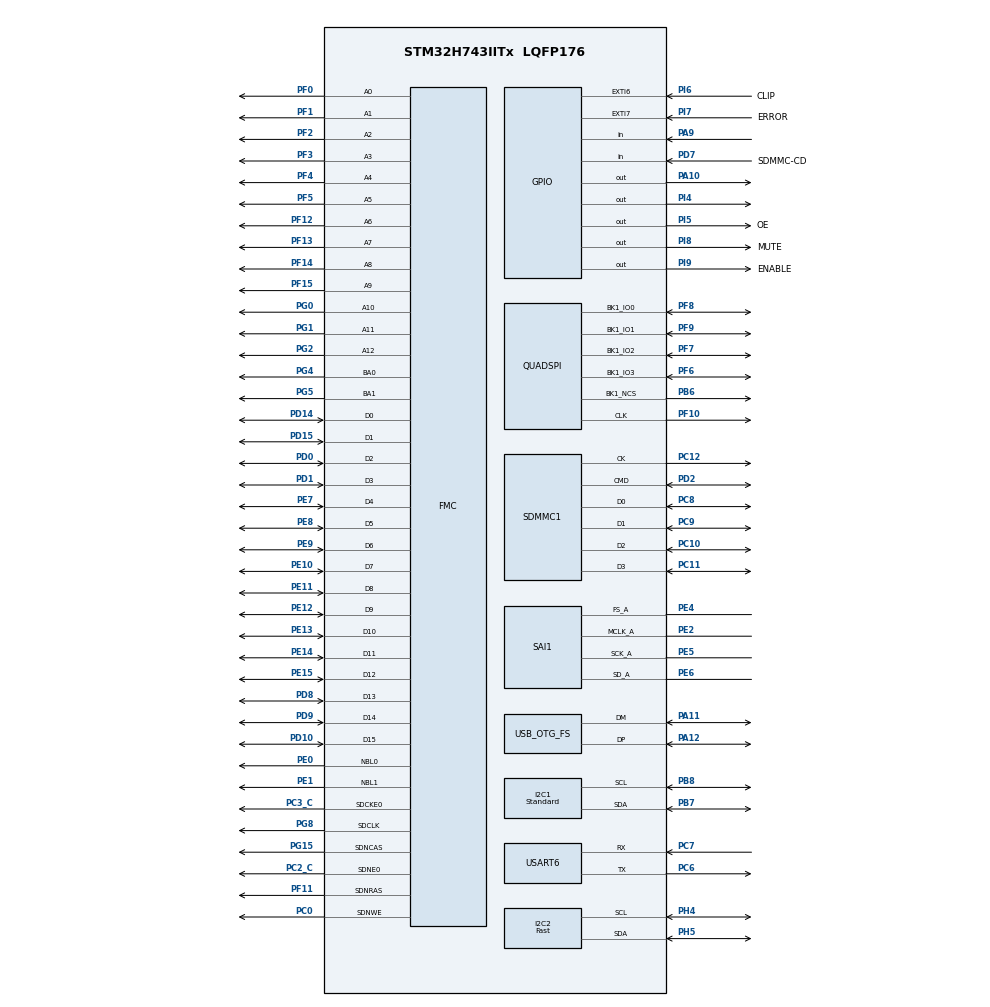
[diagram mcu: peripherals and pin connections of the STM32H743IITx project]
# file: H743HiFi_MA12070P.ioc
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CORTEX_M7.CPU_DCache=Disabled
CORTEX_M7.CPU_ICache=Disabled
CORTEX_M7.Enable_S-Cortex_Memory_Protection_Unit_Region1_Settings_S=MPU_REGION_ENABLE
CORTEX_M7.Size_Spec=MPU_REGION_SIZE_32B
CORTEX_M7.default_mode_Activation=0
Dma.I2C2_RX.0.Direction=DMA_PERIPH_TO_MEMORY
Dma.I2C2_RX.0.EventEnable=DISABLE
Dma.I2C2_RX.0.FIFOMode=DMA_FIFOMODE_DISABLE
Dma.I2C2_RX.0.Instance=DMA1_Stream0
Dma.I2C2_RX.0.MemDataAlignment=DMA_MDATAALIGN_BYTE
Dma.I2C2_RX.0.MemInc=DMA_MINC_ENABLE
Dma.I2C2_RX.0.Mode=DMA_CIRCULAR
Dma.I2C2_RX.0.PeriphDataAlignment=DMA_PDATAALIGN_BYTE
Dma.I2C2_RX.0.PeriphInc=DMA_PINC_DISABLE
Dma.I2C2_RX.0.Polarity=HAL_DMAMUX_REQ_GEN_RISING
Dma.I2C2_RX.0.Priority=DMA_PRIORITY_HIGH
Dma.I2C2_RX.0.RequestNumber=1
Dma.I2C2_RX.0.SignalID=NONE
Dma.I2C2_RX.0.SyncEnable=DISABLE
Dma.I2C2_RX.0.SyncPolarity=HAL_DMAMUX_SYNC_NO_EVENT
Dma.I2C2_RX.0.SyncRequestNumber=1
Dma.I2C2_RX.0.SyncSignalID=NONE
Dma.I2C2_TX.1.Direction=DMA_MEMORY_TO_PERIPH
Dma.I2C2_TX.1.EventEnable=DISABLE
Dma.I2C2_TX.1.FIFOMode=DMA_FIFOMODE_DISABLE
Dma.I2C2_TX.1.Instance=DMA1_Stream1
Dma.I2C2_TX.1.MemDataAlignment=DMA_MDATAALIGN_BYTE
Dma.I2C2_TX.1.MemInc=DMA_MINC_ENABLE
Dma.I2C2_TX.1.Mode=DMA_NORMAL
Dma.I2C2_TX.1.PeriphDataAlignment=DMA_PDATAALIGN_BYTE
Dma.I2C2_TX.1.PeriphInc=DMA_PINC_DISABLE
Dma.I2C2_TX.1.Polarity=HAL_DMAMUX_REQ_GEN_RISING
Dma.I2C2_TX.1.Priority=DMA_PRIORITY_HIGH
Dma.I2C2_TX.1.RequestNumber=1
Dma.I2C2_TX.1.SignalID=NONE
Dma.I2C2_TX.1.SyncEnable=DISABLE
Dma.I2C2_TX.1.SyncPolarity=HAL_DMAMUX_SYNC_NO_EVENT
Dma.I2C2_TX.1.SyncRequestNumber=1
Dma.I2C2_TX.1.SyncSignalID=NONE
Dma.Request0=I2C2_RX
Dma.Request1=I2C2_TX
Dma.Request2=SAI1_A
Dma.SAI1_A.2.Direction=DMA_MEMORY_TO_PERIPH
Dma.SAI1_A.2.EventEnable=DISABLE
Dma.SAI1_A.2.FIFOMode=DMA_FIFOMODE_ENABLE
Dma.SAI1_A.2.FIFOThreshold=DMA_FIFO_THRESHOLD_FULL
Dma.SAI1_A.2.Instance=DMA1_Stream2
Dma.SAI1_A.2.MemBurst=DMA_MBURST_SINGLE
Dma.SAI1_A.2.MemDataAlignment=DMA_MDATAALIGN_WORD
Dma.SAI1_A.2.MemInc=DMA_MINC_ENABLE
Dma.SAI1_A.2.Mode=DMA_CIRCULAR
Dma.SAI1_A.2.PeriphBurst=DMA_PBURST_SINGLE
Dma.SAI1_A.2.PeriphDataAlignment=DMA_PDATAALIGN_WORD
Dma.SAI1_A.2.PeriphInc=DMA_PINC_DISABLE
Dma.SAI1_A.2.Polarity=HAL_DMAMUX_REQ_GEN_RISING
Dma.SAI1_A.2.Priority=DMA_PRIORITY_HIGH
Dma.SAI1_A.2.RequestNumber=1
Dma.SAI1_A.2.SignalID=NONE
Dma.SAI1_A.2.SyncEnable=DISABLE
Dma.SAI1_A.2.SyncPolarity=HAL_DMAMUX_SYNC_NO_EVENT
Dma.SAI1_A.2.SyncRequestNumber=1
Dma.SAI1_A.2.SyncSignalID=NONE
FATFS.BSP.number=1
FATFS._CODE_PAGE=936
FATFS._FS_EXFAT=1
FATFS._FS_RPATH=2
FATFS._FS_TINY=0
FATFS._LFN_UNICODE=0
FATFS._MAX_SS=512
FATFS._STRF_ENCODE=0
FATFS._USE_EXPAND=1
FATFS._USE_FIND=1
FATFS._USE_FORWARD=1
FATFS._USE_LABEL=1
FATFS._USE_LFN=3
FATFS0.BSP.STBoard=false
FATFS0.BSP.api=Unknown
FATFS0.BSP.instance=PD7
FATFS0.BSP.ip=GPIO
FATFS0.BSP.mode=Input
FATFS0.BSP.name=Detect_SDIO
FATFS0.BSP.solution=PD7
FMC.BankMapConfig=FMC_SWAPBMAP_DISABLE
FMC.CASLatency1=FMC_SDRAM_CAS_LATENCY_3
FMC.ExitSelfRefreshDelay1=7
FMC.LoadToActiveDelay1=2
FMC.RCDDelay1=2
FMC.RPDelay1=2
FMC.RPDelay2=2
FMC.ReadBurst1=FMC_SDRAM_RBURST_ENABLE
FMC.ReadBurst2=FMC_SDRAM_RBURST_ENABLE
FMC.ReadPipeDelay1=FMC_SDRAM_RPIPE_DELAY_2
FMC.RowCycleDelay1=7
FMC.RowCycleDelay2=7
FMC.SDClockPeriod1=FMC_SDRAM_CLOCK_PERIOD_2
FMC.SelfRefreshTime1=4
FMC.WriteRecoveryTime1=3
FREERTOS.Tasks01=defaultTask,24,1024,StartDefaultTask,Default,NULL,Dynamic,NULL,NULL;pcm_data,8,16384,pcm_data_task,Default,NULL,Dynamic,NULL,NULL;iic_check,8,128,iic_check_task,Default,NULL,Dynamic,NULL,NULL
FREERTOS.configCHECK_FOR_STACK_OVERFLOW=1
FREERTOS.configENABLE_FPU=1
FREERTOS.configTOTAL_HEAP_SIZE=300000
FREERTOS.configUSE_NEWLIB_REENTRANT=1
I2C1.CustomTiming=Enabled
I2C1.I2C_Speed_Mode=I2C_Standard
I2C1.Speed=50
I2C1.Timing=0x00201A3B
I2C2.AddressingMode=I2C_ADDRESSINGMODE_10BIT
I2C2.DualAddressMode=I2C_DUALADDRESS_DISABLE
I2C2.GeneralCallMode=I2C_GENERALCALL_DISABLE
I2C2.I2C_Speed_Mode=I2C_Fast
I2C2.OwnAddress=0xa0
I2C2.Timing=0x00000001
Mcu.Family=STM32H7
Mcu.Name=STM32H743IITx
Mcu.Package=LQFP176
Mdma.MDMA_Channel0.QUADSPI_FIFO_TH.0.BlockCount=0
Mdma.MDMA_Channel0.QUADSPI_FIFO_TH.0.BlockDataLength=0
Mdma.MDMA_Channel0.QUADSPI_FIFO_TH.0.BufferTransferLength=1
Mdma.MDMA_Channel0.QUADSPI_FIFO_TH.0.CircularMode=MDMA_LINEAR_LIST
Mdma.MDMA_Channel0.QUADSPI_FIFO_TH.0.DataAlignment=MDMA_DATAALIGN_PACKENABLE
Mdma.MDMA_Channel0.QUADSPI_FIFO_TH.0.DestBlockAddressOffset=0
Mdma.MDMA_Channel0.QUADSPI_FIFO_TH.0.DestBurst=MDMA_DEST_BURST_SINGLE
Mdma.MDMA_Channel0.QUADSPI_FIFO_TH.0.DestDataSize=MDMA_DEST_DATASIZE_BYTE
Mdma.MDMA_Channel0.QUADSPI_FIFO_TH.0.DestinationInc=MDMA_DEST_INC_BYTE
Mdma.MDMA_Channel0.QUADSPI_FIFO_TH.0.DstAddress=0
Mdma.MDMA_Channel0.QUADSPI_FIFO_TH.0.Endianness=MDMA_LITTLE_ENDIANNESS_PRESERVE
Mdma.MDMA_Channel0.QUADSPI_FIFO_TH.0.Instance=MDMA_Channel0
Mdma.MDMA_Channel0.QUADSPI_FIFO_TH.0.MaskAddress=0
Mdma.MDMA_Channel0.QUADSPI_FIFO_TH.0.MaskData=0
Mdma.MDMA_Channel0.QUADSPI_FIFO_TH.0.Priority=MDMA_PRIORITY_LOW
Mdma.MDMA_Channel0.QUADSPI_FIFO_TH.0.Rank=First
Mdma.MDMA_Channel0.QUADSPI_FIFO_TH.0.SourceBlockAddressOffset=0
Mdma.MDMA_Channel0.QUADSPI_FIFO_TH.0.SourceBurst=MDMA_SOURCE_BURST_SINGLE
Mdma.MDMA_Channel0.QUADSPI_FIFO_TH.0.SourceDataSize=MDMA_SRC_DATASIZE_BYTE
Mdma.MDMA_Channel0.QUADSPI_FIFO_TH.0.SourceInc=MDMA_SRC_INC_BYTE
Mdma.MDMA_Channel0.QUADSPI_FIFO_TH.0.SrcAddress=0
Mdma.MDMA_Channel0.QUADSPI_FIFO_TH.0.TransferTriggerMode=MDMA_BUFFER_TRANSFER
Mdma.MDMA_Channel0.Request0=QUADSPI_FIFO_TH
Mdma.MDMA_Channel0.RequestsNb=1
Mdma.MDMA_Channel1.Request0=SDMMC1_END_DATA
Mdma.MDMA_Channel1.RequestsNb=1
Mdma.MDMA_Channel1.SDMMC1_END_DATA.0.BlockCount=0
Mdma.MDMA_Channel1.SDMMC1_END_DATA.0.BlockDataLength=0
Mdma.MDMA_Channel1.SDMMC1_END_DATA.0.BufferTransferLength=1
Mdma.MDMA_Channel1.SDMMC1_END_DATA.0.CircularMode=MDMA_LINEAR_LIST
Mdma.MDMA_Channel1.SDMMC1_END_DATA.0.DataAlignment=MDMA_DATAALIGN_PACKENABLE
Mdma.MDMA_Channel1.SDMMC1_END_DATA.0.DestBlockAddressOffset=0
Mdma.MDMA_Channel1.SDMMC1_END_DATA.0.DestBurst=MDMA_DEST_BURST_SINGLE
Mdma.MDMA_Channel1.SDMMC1_END_DATA.0.DestDataSize=MDMA_DEST_DATASIZE_BYTE
Mdma.MDMA_Channel1.SDMMC1_END_DATA.0.DestinationInc=MDMA_DEST_INC_BYTE
Mdma.MDMA_Channel1.SDMMC1_END_DATA.0.DstAddress=0
Mdma.MDMA_Channel1.SDMMC1_END_DATA.0.Endianness=MDMA_LITTLE_ENDIANNESS_PRESERVE
Mdma.MDMA_Channel1.SDMMC1_END_DATA.0.Instance=MDMA_Channel1
Mdma.MDMA_Channel1.SDMMC1_END_DATA.0.MaskAddress=0
Mdma.MDMA_Channel1.SDMMC1_END_DATA.0.MaskData=0
Mdma.MDMA_Channel1.SDMMC1_END_DATA.0.Priority=MDMA_PRIORITY_LOW
Mdma.MDMA_Channel1.SDMMC1_END_DATA.0.Rank=First
Mdma.MDMA_Channel1.SDMMC1_END_DATA.0.SourceBlockAddressOffset=0
Mdma.MDMA_Channel1.SDMMC1_END_DATA.0.SourceBurst=MDMA_SOURCE_BURST_SINGLE
Mdma.MDMA_Channel1.SDMMC1_END_DATA.0.SourceDataSize=MDMA_SRC_DATASIZE_BYTE
Mdma.MDMA_Channel1.SDMMC1_END_DATA.0.SourceInc=MDMA_SRC_INC_BYTE
Mdma.MDMA_Channel1.SDMMC1_END_DATA.0.SrcAddress=0
Mdma.MDMA_Channel1.SDMMC1_END_DATA.0.TransferTriggerMode=MDMA_BUFFER_TRANSFER
Mdma.RequestSet0=MDMA_Channel0
Mdma.RequestSet1=MDMA_Channel1
Mdma.RequestSetsNb=2
NVIC.DMA1_Stream0_IRQn=true\:5\:0\:false\:false\:true\:true\:false\:true\:true
NVIC.DMA1_Stream1_IRQn=true\:5\:0\:false\:false\:true\:true\:false\:true\:true
NVIC.DMA1_Stream2_IRQn=true\:5\:0\:false\:false\:true\:true\:false\:true\:true
NVIC.I2C1_ER_IRQn=true\:5\:0\:false\:false\:true\:true\:true\:true\:true
NVIC.I2C1_EV_IRQn=true\:5\:0\:false\:false\:true\:true\:true\:true\:true
NVIC.MDMA_IRQn=true\:5\:0\:false\:false\:true\:true\:false\:true\:true
NVIC.OTG_FS_IRQn=true\:5\:0\:true\:false\:true\:true\:false\:true\:true
NVIC.PriorityGroup=NVIC_PRIORITYGROUP_4
NVIC.SDMMC1_IRQn=true\:5\:0\:true\:false\:true\:true\:true\:true\:true
NVIC.TIM6_DAC_IRQn=true\:0\:0\:true\:false\:true\:false\:false\:true\:true
NVIC.TimeBase=TIM6_DAC_IRQn
NVIC.TimeBaseIP=TIM6
PA10.GPIO_ModeDefaultOutputPP=GPIO_MODE_OUTPUT_OD
PA10.GPIO_PuPd=GPIO_NOPULL
PA10.PinState=GPIO_PIN_SET
PA10.Signal=GPIO_Output
PA11.Mode=Device_Only
PA11.Signal=USB_OTG_FS_DM
PA12.Mode=Device_Only
PA12.Signal=USB_OTG_FS_DP
PA13\ (JTMS/SWDIO).Mode=Serial_Wire
PA13\ (JTMS/SWDIO).Signal=DEBUG_JTMS-SWDIO
PA14\ (JTCK/SWCLK).Mode=Serial_Wire
PA14\ (JTCK/SWCLK).Signal=DEBUG_JTCK-SWCLK
PA9.GPIO_PuPd=GPIO_NOPULL
PA9.Signal=GPIO_Input
PB6.Mode=Single Bank 1
PB6.Signal=QUADSPI_BK1_NCS
PB7.GPIO_Pu=GPIO_NOPULL
PB7.Mode=I2C
PB7.Signal=I2C1_SDA
PB8.GPIO_Pu=GPIO_NOPULL
PB8.Mode=I2C
PB8.Signal=I2C1_SCL
PC0.Signal=FMC_SDNWE
PC10.Mode=SD_4_bits_Wide_bus
PC10.Signal=SDMMC1_D2
PC11.Mode=SD_4_bits_Wide_bus
PC11.Signal=SDMMC1_D3
PC12.Mode=SD_4_bits_Wide_bus
PC12.Signal=SDMMC1_CK
PC14-OSC32_IN\ (OSC32_IN).Mode=LSE-External-Oscillator
PC14-OSC32_IN\ (OSC32_IN).PinAttribute=Free
PC14-OSC32_IN\ (OSC32_IN).Signal=RCC_OSC32_IN
PC15-OSC32_OUT\ (OSC32_OUT).Mode=LSE-External-Oscillator
PC15-OSC32_OUT\ (OSC32_OUT).PinAttribute=Free
PC15-OSC32_OUT\ (OSC32_OUT).Signal=RCC_OSC32_OUT
PC2_C.Mode=SdramChipSelect1_1
PC2_C.Signal=FMC_SDNE0
PC3_C.Mode=SdramChipSelect1_1
PC3_C.Signal=FMC_SDCKE0
PC6.Mode=Asynchronous
PC6.Signal=USART6_TX
PC7.Mode=Asynchronous
PC7.Signal=USART6_RX
PC8.Mode=SD_4_bits_Wide_bus
PC8.Signal=SDMMC1_D0
PC9.Mode=SD_4_bits_Wide_bus
PC9.Signal=SDMMC1_D1
PD0.Signal=FMC_D2_DA2
PD1.Signal=FMC_D3_DA3
PD10.Signal=FMC_D15_DA15
PD14.Signal=FMC_D0_DA0
PD15.Signal=FMC_D1_DA1
PD2.Mode=SD_4_bits_Wide_bus
PD2.Signal=SDMMC1_CMD
PD7.GPIO_Label=SDMMC-CD
PD7.Signal=GPIO_Input
PD8.Signal=FMC_D13_DA13
PD9.Signal=FMC_D14_DA14
PE0.Signal=FMC_NBL0
PE1.Signal=FMC_NBL1
PE10.Signal=FMC_D7_DA7
PE11.Signal=FMC_D8_DA8
PE12.Signal=FMC_D9_DA9
PE13.Signal=FMC_D10_DA10
PE14.Signal=FMC_D11_DA11
PE15.Signal=FMC_D12_DA12
PE2.GPIO_Speed=GPIO_SPEED_FREQ_VERY_HIGH
PE2.Mode=SAI_A_MasterWithClock
PE2.PinAttribute=Free
PE2.Signal=SAI1_MCLK_A
PE4.GPIO_Speed=GPIO_SPEED_FREQ_VERY_HIGH
PE4.Mode=SAI_A_MasterWithClock
PE4.PinAttribute=Free
PE4.Signal=SAI1_FS_A
PE5.GPIO_Speed=GPIO_SPEED_FREQ_VERY_HIGH
PE5.Mode=SAI_A_MasterWithClock
PE5.PinAttribute=Free
PE5.Signal=SAI1_SCK_A
PE6.GPIO_Speed=GPIO_SPEED_FREQ_VERY_HIGH
PE6.Mode=SAI_A_MasterWithClock
PE6.PinAttribute=Free
PE6.Signal=SAI1_SD_A
PE7.Signal=FMC_D4_DA4
PE8.Signal=FMC_D5_DA5
PE9.Signal=FMC_D6_DA6
PF0.Signal=FMC_A0
PF1.Signal=FMC_A1
PF10.Mode=Single Bank 1
PF10.Signal=QUADSPI_CLK
PF11.Signal=FMC_SDNRAS
PF12.Signal=FMC_A6
PF13.Signal=FMC_A7
PF14.Signal=FMC_A8
PF15.Signal=FMC_A9
PF2.Signal=FMC_A2
PF3.Signal=FMC_A3
PF4.Signal=FMC_A4
PF5.Signal=FMC_A5
PF6.Mode=Single Bank 1
PF6.Signal=QUADSPI_BK1_IO3
PF7.Mode=Single Bank 1
PF7.Signal=QUADSPI_BK1_IO2
PF8.Mode=Single Bank 1
PF8.Signal=QUADSPI_BK1_IO0
PF9.Mode=Single Bank 1
PF9.Signal=QUADSPI_BK1_IO1
PG0.Signal=FMC_A10
PG1.Signal=FMC_A11
PG15.Signal=FMC_SDNCAS
PG2.Signal=FMC_A12
PG4.Signal=FMC_A14_BA0
PG5.Signal=FMC_A15_BA1
PG8.Signal=FMC_SDCLK
PH0-OSC_IN\ (PH0).Mode=HSE-External-Oscillator
PH0-OSC_IN\ (PH0).Signal=RCC_OSC_IN
PH1-OSC_OUT\ (PH1).Mode=HSE-External-Oscillator
PH1-OSC_OUT\ (PH1).Signal=RCC_OSC_OUT
PH4.Mode=I2C
PH4.Signal=I2C2_SCL
PH5.Mode=I2C
PH5.Signal=I2C2_SDA
PI4.GPIO_ModeDefaultOutputPP=GPIO_MODE_OUTPUT_OD
PI4.GPIO_PuPd=GPIO_NOPULL
PI4.PinState=GPIO_PIN_SET
PI4.Signal=GPIO_Output
PI5.GPIO_Label=OE
PI5.GPIO_ModeDefaultOutputPP=GPIO_MODE_OUTPUT_PP
PI5.GPIO_PuPd=GPIO_NOPULL
PI5.Signal=GPIO_Output
PI6.GPIO_Label=CLIP
PI6.GPIO_ModeDefaultEXTI=GPIO_MODE_IT_FALLING
PI6.GPIO_PuPd=GPIO_PULLUP
PI6.Signal=GPXTI6
PI7.GPIO_Label=ERROR
PI7.GPIO_ModeDefaultEXTI=GPIO_MODE_IT_FALLING
PI7.GPIO_PuPd=GPIO_PULLUP
PI7.Signal=GPXTI7
PI8.GPIO_Label=MUTE
PI8.PinAttribute=Free
PI8.Signal=GPIO_Output
PI9.GPIO_Label=ENABLE
PI9.GPIO_ModeDefaultOutputPP=GPIO_MODE_OUTPUT_OD
PI9.GPIO_PuPd=GPIO_NOPULL
PI9.PinAttribute=Free
PI9.PinState=GPIO_PIN_SET
PI9.Signal=GPIO_Output
ProjectManager.HeapSize=0x2000
ProjectManager.StackSize=0x4000
ProjectManager.TargetToolchain=STM32CubeIDE
RCC.ADCFreq_Value=11289599.609375
RCC.APB1Freq_Value=59000000
RCC.APB2Freq_Value=59000000
RCC.APB3Freq_Value=59000000
RCC.APB4Freq_Value=59000000
RCC.CKPERSourceSelection=RCC_CLKPSOURCE_HSE
RCC.CortexFreq_Value=59000000
RCC.Cortex_Div=SYSTICK_CLKSOURCE_HCLK_DIV8
RCC.D1PPRE=RCC_APB3_DIV2
RCC.D2PPRE1=RCC_APB1_DIV2
RCC.D2PPRE2=RCC_APB2_DIV2
RCC.D3PPRE=RCC_APB4_DIV2
RCC.DIVM1=1
RCC.DIVM2=4
RCC.DIVM3=5
RCC.DIVN1=118
RCC.DIVN2=254
RCC.DIVN3=245
RCC.DIVP2=45
RCC.DIVP3=32
RCC.DIVQ1=10
RCC.DIVQ3=5
RCC.DIVR2=20
RCC.DIVR3=128
RCC.HCLKFreq_Value=118000000
RCC.HPRE=RCC_HCLK_DIV4
RCC.HSE_VALUE=8000000
RCC.I2C123CLockSelection=RCC_I2C123CLKSOURCE_PLL3
RCC.PLL2FRACN=131
RCC.PLL3FRACN=6390
RCC.PLLFRACN=0
RCC.PLLSourceVirtual=RCC_PLLSOURCE_HSE
RCC.SAI1CLockSelection=RCC_SAI1CLKSOURCE_PLL2
RCC.SDMMC1CLockSelection=RCC_SDMMCCLKSOURCE_PLL2
RCC.SYSCLKFreq_VALUE=472000000
RCC.SYSCLKSource=RCC_SYSCLKSOURCE_PLLCLK
RCC.USBCLockSelection=RCC_USBCLKSOURCE_HSI48
RCC.USBFreq_Value=48000000
SAI1.ErrorAudioFreq-SAI_A_MasterWithClock=-77.03 %
SAI1.Instance-SAI_A_MasterWithClock=SAI$Index_Block_A
SAI1.MClockEnable-SAI_A_MasterWithClock=SAI_MASTERCLOCK_ENABLE
SAI1.RealAudioFreq-SAI_A_MasterWithClock=44.099 KHz
SAI1.VirtualMode-SAI_A_MasterWithClock=VM_MASTER
SDMMC1.ClockDiv=2
SDMMC1.HardwareFlowControl=SDMMC_HARDWARE_FLOW_CONTROL_ENABLE
SH.FMC_A0.0=FMC_A0,13b-sda1
SH.FMC_A1.0=FMC_A1,13b-sda1
SH.FMC_A10.0=FMC_A10,13b-sda1
SH.FMC_A11.0=FMC_A11,13b-sda1
SH.FMC_A12.0=FMC_A12,13b-sda1
SH.FMC_A14_BA0.0=FMC_BA0,FourSdramBanks1
SH.FMC_A15_BA1.0=FMC_BA1,FourSdramBanks1
SH.FMC_A2.0=FMC_A2,13b-sda1
SH.FMC_A3.0=FMC_A3,13b-sda1
SH.FMC_A4.0=FMC_A4,13b-sda1
SH.FMC_A5.0=FMC_A5,13b-sda1
SH.FMC_A6.0=FMC_A6,13b-sda1
SH.FMC_A7.0=FMC_A7,13b-sda1
SH.FMC_A8.0=FMC_A8,13b-sda1
SH.FMC_A9.0=FMC_A9,13b-sda1
SH.FMC_D0_DA0.0=FMC_D0,sd-16b-d1
SH.FMC_D10_DA10.0=FMC_D10,sd-16b-d1
SH.FMC_D11_DA11.0=FMC_D11,sd-16b-d1
SH.FMC_D12_DA12.0=FMC_D12,sd-16b-d1
SH.FMC_D13_DA13.0=FMC_D13,sd-16b-d1
SH.FMC_D14_DA14.0=FMC_D14,sd-16b-d1
SH.FMC_D15_DA15.0=FMC_D15,sd-16b-d1
SH.FMC_D1_DA1.0=FMC_D1,sd-16b-d1
SH.FMC_D2_DA2.0=FMC_D2,sd-16b-d1
SH.FMC_D3_DA3.0=FMC_D3,sd-16b-d1
SH.FMC_D4_DA4.0=FMC_D4,sd-16b-d1
SH.FMC_D5_DA5.0=FMC_D5,sd-16b-d1
SH.FMC_D6_DA6.0=FMC_D6,sd-16b-d1
SH.FMC_D7_DA7.0=FMC_D7,sd-16b-d1
SH.FMC_D8_DA8.0=FMC_D8,sd-16b-d1
SH.FMC_D9_DA9.0=FMC_D9,sd-16b-d1
SH.FMC_NBL0.0=FMC_NBL0,Sd2ByteEnable1
SH.FMC_NBL1.0=FMC_NBL1,Sd2ByteEnable1
SH.FMC_SDCLK.0=FMC_SDCLK,13b-sda1
SH.FMC_SDNCAS.0=FMC_SDNCAS,13b-sda1
SH.FMC_SDNRAS.0=FMC_SDNRAS,13b-sda1
SH.FMC_SDNWE.0=FMC_SDNWE,13b-sda1
USART6.VirtualMode-Asynchronous=VM_ASYNC
USB_DEVICE.CLASS_NAME_FS=MSC
USB_DEVICE.MSC_MEDIA_PACKET-MSC_FS=8192
USB_DEVICE.VirtualMode-MSC_FS=Msc
USB_DEVICE.VirtualModeFS=Msc_FS
USB_OTG_FS.VirtualMode=Device_Only
USB_OTG_FS.battery_charging_enable=DISABLE
USB_OTG_FS.dma_enable=ENABLE
VP_CRC_VS_CRC.Mode=CRC_Activate
VP_FATFS_VS_SDIO.Mode=SDIO
VP_FREERTOS_VS_CMSIS_V2.Mode=CMSIS_V2
VP_MEMORYMAP_VS_MEMORYMAP.Mode=CurAppReg
VP_SYS_VS_tim6.Mode=TIM6
VP_USB_DEVICE_VS_USB_DEVICE_MSC_FS.Mode=MSC_FS
board=custom

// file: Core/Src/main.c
/* USER CODE BEGIN Header */
/**
  ******************************************************************************
  * @file           : main.c
  * @brief          : Main program body
  ******************************************************************************
  * @attention
  *
  * Copyright (c) 2025 STMicroelectronics.
  * All rights reserved.
  *
  * This software is licensed under terms that can be found in the LICENSE file
  * in the root directory of this software component.
  * If no LICENSE file comes with this software, it is provided AS-IS.
  *
  ******************************************************************************
  */
/* USER CODE END Header */
#include "main.h"
#include "cmsis_os.h"
#include "crc.h"
#include "dma.h"
#include "fatfs.h"
#include "i2c.h"
#include "mdma.h"
#include "memorymap.h"
#include "quadspi.h"
#include "sai.h"
#include "sdmmc.h"
#include "usart.h"
#include "usb_device.h"
#include "gpio.h"
#include "fmc.h"

/* USER CODE BEGIN Includes */
#include "dbgu.h"
/* USER CODE END Includes */

void SystemClock_Config(void);
void PeriphCommonClock_Config(void);
void MX_FREERTOS_Init(void);

int main(void)
{

  /* MCU Configuration--------------------------------------------------------*/

  /* Reset of all peripherals, Initializes the Flash interface and the Systick. */
  HAL_Init();

  /* USER CODE BEGIN Init */
  //避免在SystemClock_Config中卡死
  //MX_IWDG1_Init();
  /* USER CODE END Init */

  /* Configure the system clock */
  SystemClock_Config();

  /* Configure the peripherals common clocks */
  PeriphCommonClock_Config();

  /* Initialize all configured peripherals */
  MX_GPIO_Init();
  MX_DMA_Init();
  MX_MDMA_Init();
  MX_I2C1_Init();
  MX_FMC_Init();
  MX_I2C2_Init();
  MX_SDMMC1_SD_Init();
  MX_SAI1_Init();
  MX_CRC_Init();
  MX_USART6_UART_Init();
  MX_FATFS_Init();
  MX_QUADSPI_Init();
  /* USER CODE BEGIN 2 */

	if (HAL_GPIO_ReadPin(GPIOA, GPIO_PIN_9) == GPIO_PIN_SET) {
	  HAL_Delay(20);  // 确认低电平稳定
	  if (HAL_GPIO_ReadPin(GPIOA, GPIO_PIN_9) == GPIO_PIN_SET)
	  {
		  HAL_GPIO_WritePin(GPIOA, GPIO_PIN_10, GPIO_PIN_RESET);
	  }
	}

  HAL_GPIO_WritePin(ENABLE_GPIO_Port, ENABLE_Pin, GPIO_PIN_SET);

  debug_init(&huart6);

  HAL_GPIO_WritePin(OE_GPIO_Port, OE_Pin, GPIO_PIN_SET);

#define SDRAM_BASE_ADDR 0xC0000000

  int * pSDRAM = (int*)SDRAM_BASE_ADDR;
  for (int i=0; i<1000; i++)
  {
	  pSDRAM[i] = i;
  }
  for (int i=0; i<1000; i++)
  {
	  if (pSDRAM[i] != i)
	  {
		  printf("sdram1 error\r\n");
	  }
  }
  /*
  HAL_GPIO_WritePin(ENABLE_GPIO_Port, ENABLE_Pin, GPIO_PIN_RESET);
  HAL_Delay(1000);
  while (1)
  {
       HAL_StatusTypeDef status = HAL_I2C_IsDeviceReady(&hi2c1, 0x20 << 1, 3, 100);
	   if(status == HAL_OK) {
	      printf("PCF8591 found at 0x%02X\n", 0x20);
	   }
	  uint8_t value = 15;
	  status = HAL_I2C_Mem_Write(&hi2c1, 0x20<<1, 53,
	  	   	                                 I2C_MEMADD_SIZE_8BIT, &value, 1, 100);

   HAL_Delay(1);
  }

   uint8_t ctrlByte = 127;  // 读取控制寄存器默认值
   uint8_t readBuf[2];
   HAL_StatusTypeDef status = HAL_I2C_Master_Transmit(&hi2c1, 0x20 << 1, &ctrlByte, 1, 10);
   HAL_Delay(1);
   status = HAL_I2C_Master_Receive(&hi2c1, (0x20 << 1) | 0x01, readBuf, 1, 20);

   status = HAL_I2C_Mem_Read(
 	            &hi2c1,
 				0x20 << 1,
 				ctrlByte,
 				I2C_MEMADD_SIZE_8BIT,
 				readBuf,
 	            2,
 				HAL_MAX_DELAY);

   status = HAL_I2C_Mem_Read(&hi2c1, 0x20 << 1, (uint16_t)0, I2C_MEMADD_SIZE_8BIT, (uint8_t*)readBuf, 1, 1000);
 //*/

   BSP_SD_Init();

  /* USER CODE END 2 */

  /* Init scheduler */
  osKernelInitialize();

  /* Call init function for freertos objects (in cmsis_os2.c) */
  MX_FREERTOS_Init();

  /* Start scheduler */
  osKernelStart();

  /* We should never get here as control is now taken by the scheduler */

  /* Infinite loop */
  while (1)
  {

  }
}

void SystemClock_Config(void)
{
  RCC_OscInitTypeDef RCC_OscInitStruct = {0};
  RCC_ClkInitTypeDef RCC_ClkInitStruct = {0};

  /** Supply configuration update enable
  */
  HAL_PWREx_ConfigSupply(PWR_LDO_SUPPLY);

  /** Configure the main internal regulator output voltage
  */
  __HAL_PWR_VOLTAGESCALING_CONFIG(PWR_REGULATOR_VOLTAGE_SCALE0);

  while(!__HAL_PWR_GET_FLAG(PWR_FLAG_VOSRDY)) {}

  /** Initializes the RCC Oscillators according to the specified parameters
  * in the RCC_OscInitTypeDef structure.
  */
  RCC_OscInitStruct.OscillatorType = RCC_OSCILLATORTYPE_HSI48|RCC_OSCILLATORTYPE_HSE;
  RCC_OscInitStruct.HSEState = RCC_HSE_ON;
  RCC_OscInitStruct.HSI48State = RCC_HSI48_ON;
  RCC_OscInitStruct.PLL.PLLState = RCC_PLL_ON;
  RCC_OscInitStruct.PLL.PLLSource = RCC_PLLSOURCE_HSE;
  RCC_OscInitStruct.PLL.PLLM = 1;
  RCC_OscInitStruct.PLL.PLLN = 118;
  RCC_OscInitStruct.PLL.PLLP = 2;
  RCC_OscInitStruct.PLL.PLLQ = 10;
  RCC_OscInitStruct.PLL.PLLR = 2;
  RCC_OscInitStruct.PLL.PLLRGE = RCC_PLL1VCIRANGE_3;
  RCC_OscInitStruct.PLL.PLLVCOSEL = RCC_PLL1VCOWIDE;
  RCC_OscInitStruct.PLL.PLLFRACN = 0;
  if (HAL_RCC_OscConfig(&RCC_OscInitStruct) != HAL_OK)
  {
    Error_Handler();
  }

  /** Initializes the CPU, AHB and APB buses clocks
  */
  RCC_ClkInitStruct.ClockType = RCC_CLOCKTYPE_HCLK|RCC_CLOCKTYPE_SYSCLK
                              |RCC_CLOCKTYPE_PCLK1|RCC_CLOCKTYPE_PCLK2
                              |RCC_CLOCKTYPE_D3PCLK1|RCC_CLOCKTYPE_D1PCLK1;
  RCC_ClkInitStruct.SYSCLKSource = RCC_SYSCLKSOURCE_PLLCLK;
  RCC_ClkInitStruct.SYSCLKDivider = RCC_SYSCLK_DIV1;
  RCC_ClkInitStruct.AHBCLKDivider = RCC_HCLK_DIV4;
  RCC_ClkInitStruct.APB3CLKDivider = RCC_APB3_DIV2;
  RCC_ClkInitStruct.APB1CLKDivider = RCC_APB1_DIV2;
  RCC_ClkInitStruct.APB2CLKDivider = RCC_APB2_DIV2;
  RCC_ClkInitStruct.APB4CLKDivider = RCC_APB4_DIV2;

  if (HAL_RCC_ClockConfig(&RCC_ClkInitStruct, FLASH_LATENCY_1) != HAL_OK)
  {
    Error_Handler();
  }
}

void PeriphCommonClock_Config(void)
{
  RCC_PeriphCLKInitTypeDef PeriphClkInitStruct = {0};

  /** Initializes the peripherals clock
  */
  PeriphClkInitStruct.PeriphClockSelection = RCC_PERIPHCLK_I2C2|RCC_PERIPHCLK_I2C1
                              |RCC_PERIPHCLK_SDMMC|RCC_PERIPHCLK_SAI1;
  PeriphClkInitStruct.PLL2.PLL2M = 4;
  PeriphClkInitStruct.PLL2.PLL2N = 254;
  PeriphClkInitStruct.PLL2.PLL2P = 45;
  PeriphClkInitStruct.PLL2.PLL2Q = 2;
  PeriphClkInitStruct.PLL2.PLL2R = 20;
  PeriphClkInitStruct.PLL2.PLL2RGE = RCC_PLL2VCIRANGE_1;
  PeriphClkInitStruct.PLL2.PLL2VCOSEL = RCC_PLL2VCOWIDE;
  PeriphClkInitStruct.PLL2.PLL2FRACN = 131;
  PeriphClkInitStruct.PLL3.PLL3M = 5;
  PeriphClkInitStruct.PLL3.PLL3N = 245;
  PeriphClkInitStruct.PLL3.PLL3P = 32;
  PeriphClkInitStruct.PLL3.PLL3Q = 5;
  PeriphClkInitStruct.PLL3.PLL3R = 128;
  PeriphClkInitStruct.PLL3.PLL3RGE = RCC_PLL3VCIRANGE_0;
  PeriphClkInitStruct.PLL3.PLL3VCOSEL = RCC_PLL3VCOWIDE;
  PeriphClkInitStruct.PLL3.PLL3FRACN = 6390;
  PeriphClkInitStruct.SdmmcClockSelection = RCC_SDMMCCLKSOURCE_PLL2;
  PeriphClkInitStruct.Sai1ClockSelection = RCC_SAI1CLKSOURCE_PLL2;
  PeriphClkInitStruct.I2c123ClockSelection = RCC_I2C123CLKSOURCE_PLL3;
  if (HAL_RCCEx_PeriphCLKConfig(&PeriphClkInitStruct) != HAL_OK)
  {
    Error_Handler();
  }
}

void HAL_TIM_PeriodElapsedCallback(TIM_HandleTypeDef *htim)
{
  if (htim->Instance == TIM6)
  {
    HAL_IncTick();
  }
}

void Error_Handler(void)
{
  /* USER CODE BEGIN Error_Handler_Debug */
  /* User can add his own implementation to report the HAL error return state */
  __disable_irq();
  while (1)
  {
	//__set_FAULTMASK(1);  // 关闭所有中断
	//NVIC_SystemReset();  // 进行软件复位
  }
  /* USER CODE END Error_Handler_Debug */
}

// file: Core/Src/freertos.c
/* USER CODE BEGIN Header */
/**
  ******************************************************************************
  * File Name          : freertos.c
  * Description        : Code for freertos applications
  ******************************************************************************
  * @attention
  *
  * Copyright (c) 2025 STMicroelectronics.
  * All rights reserved.
  *
  * This software is licensed under terms that can be found in the LICENSE file
  * in the root directory of this software component.
  * If no LICENSE file comes with this software, it is provided AS-IS.
  *
  ******************************************************************************
  */
/* USER CODE END Header */

#include "FreeRTOS.h"
#include "task.h"
#include "main.h"
#include "cmsis_os.h"

/* USER CODE BEGIN Includes */
#include "controller.h"
//#include "iwdg.h"
/* USER CODE END Includes */

/* Definitions for defaultTask */
osThreadId_t defaultTaskHandle;
const osThreadAttr_t defaultTask_attributes = {
  .name = "defaultTask",
  .stack_size = 1024 * 4,
  .priority = (osPriority_t) osPriorityNormal,
};
/* Definitions for pcm_data */
osThreadId_t pcm_dataHandle;
const osThreadAttr_t pcm_data_attributes = {
  .name = "pcm_data",
  .stack_size = 16384 * 4,
  .priority = (osPriority_t) osPriorityLow,
};
/* Definitions for iic_check */
osThreadId_t iic_checkHandle;
const osThreadAttr_t iic_check_attributes = {
  .name = "iic_check",
  .stack_size = 128 * 4,
  .priority = (osPriority_t) osPriorityLow,
};

void StartDefaultTask(void *argument);
void pcm_data_task(void *argument);
void iic_check_task(void *argument);

extern void MX_USB_DEVICE_Init(void);
void MX_FREERTOS_Init(void); /* (MISRA C 2004 rule 8.1) */

/* Hook prototypes */
void vApplicationStackOverflowHook(xTaskHandle xTask, signed char *pcTaskName);

/* USER CODE BEGIN 4 */
void vApplicationStackOverflowHook(xTaskHandle xTask, signed char *pcTaskName)
{
   /* Run time stack overflow checking is performed if
   configCHECK_FOR_STACK_OVERFLOW is defined to 1 or 2. This hook function is
   called if a stack overflow is detected. */
}
/* USER CODE END 4 */

void MX_FREERTOS_Init(void) {

  /* Create the thread(s) */
  /* creation of defaultTask */
  defaultTaskHandle = osThreadNew(StartDefaultTask, NULL, &defaultTask_attributes);

  /* creation of pcm_data */
  pcm_dataHandle = osThreadNew(pcm_data_task, NULL, &pcm_data_attributes);

  /* creation of iic_check */
  iic_checkHandle = osThreadNew(iic_check_task, NULL, &iic_check_attributes);

}

void StartDefaultTask(void *argument)
{
  /* init code for USB_DEVICE */
  MX_USB_DEVICE_Init();
  /* USER CODE BEGIN StartDefaultTask */
  /* Infinite loop */
  for(;;)
  {
	  //HAL_IWDG_Refresh(&hiwdg1);
    osDelay(100);
  }
  /* USER CODE END StartDefaultTask */
}

void pcm_data_task(void *argument)
{
  /* USER CODE BEGIN pcm_data_task */

  controller_task();

  /* Infinite loop */
  for(;;)
  {
    osDelay(1);
  }
  /* USER CODE END pcm_data_task */
}

void iic_check_task(void *argument)
{
  /* USER CODE BEGIN iic_check_task */
  /* Infinite loop */

	check_task();
  for(;;)
  {
    osDelay(1);
  }
  /* USER CODE END iic_check_task */
}
